# STM32H533 register map
File version: 1.3
CPU: CM33 r0p0, little endian, MPU, FPU, 4 interrupt priority bits
Registers are 32-bit, read-write, reset 0x0 unless marked. A register's access mark holds for its fields unless they carry their own. Offsets are from the block's base; [hi:lo] are bit positions; {n}, {i} and the like mark numbered series.

## CRS — CRS address block description
Base 0x40006000
Same registers: CRS_S 0x50006000
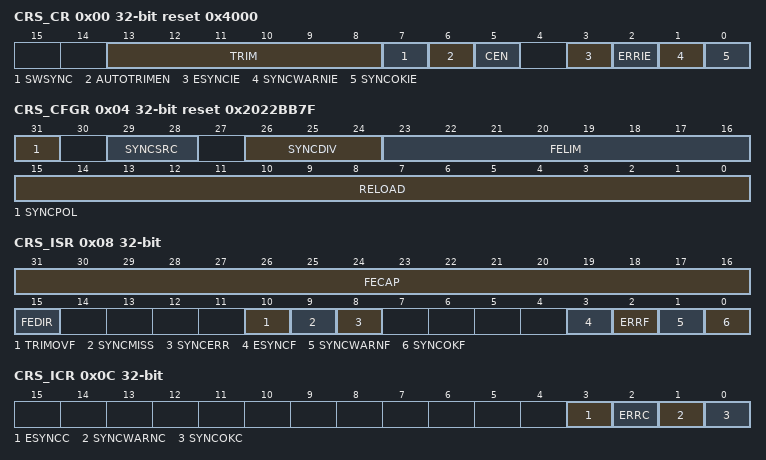
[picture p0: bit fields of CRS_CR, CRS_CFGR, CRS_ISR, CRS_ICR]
0x00 CRS_CR reset 0x4000 — CRS control register
  [13:8] TRIM — HSI48 oscillator smooth trimming
  [7] SWSYNC — Generate software SYNC event
    0=No action; 1=A software SYNC event is generated
  [6] AUTOTRIMEN — Automatic trimming enable
    0=Automatic trimming disabled, TRIM bits can be adjusted by the user; 1=Automatic trimming enabled, TRIM bits are read-only and under hardware control
  [5] CEN — Frequency error counter enable
    0=Frequency error counter disabled; 1=Frequency error counter enabled
  [3] ESYNCIE — Expected SYNC interrupt enable
    0=Expected SYNC (ESYNCF) interrupt disabled; 1=Expected SYNC (ESYNCF) interrupt enabled
  [2] ERRIE — Synchronization or trimming error interrupt enable
    0=Synchronization or trimming error (ERRF) interrupt disabled; 1=Synchronization or trimming error (ERRF) interrupt enabled
  [1] SYNCWARNIE — SYNC warning interrupt enable
    0=SYNC warning (SYNCWARNF) interrupt disabled; 1=SYNC warning (SYNCWARNF) interrupt enabled
  [0] SYNCOKIE — SYNC event OK interrupt enable
    0=SYNC event OK (SYNCOKF) interrupt disabled; 1=SYNC event OK (SYNCOKF) interrupt enabled
0x04 CRS_CFGR reset 0x2022BB7F — CRS configuration register
  [31] SYNCPOL — SYNC polarity selection
    0=SYNC active on rising edge (default); 1=SYNC active on falling edge
  [29:28] SYNCSRC — SYNC signal source selection
    {v}=crs_sync_in_{v+1} selected as SYNC signal source (v=0..3)
  [26:24] SYNCDIV — SYNC divider
    0=SYNC not divided (default); 1=SYNC divided by 2; 2=SYNC divided by 4; 3=SYNC divided by 8; 4=SYNC divided by 16; 5=SYNC divided by 32; 6=SYNC divided by 64; 7=SYNC divided by 128
  [23:16] FELIM — Frequency error limit
  [15:0] RELOAD — Counter reload value
0x08 CRS_ISR ro — CRS interrupt and status register
  [31:16] FECAP — Frequency error capture
  [15] FEDIR — Frequency error direction
    0=Up-counting direction, the actual frequency is above the target; 1=Down-counting direction, the actual frequency is below the target
  [10] TRIMOVF — Trimming overflow or underflow
    0=No trimming error signaled; 1=Trimming error signaled
  [9] SYNCMISS — SYNC missed
    0=No SYNC missed error signaled; 1=SYNC missed error signaled
  [8] SYNCERR — SYNC error
    0=No SYNC error signaled; 1=SYNC error signaled
  [3] ESYNCF — Expected SYNC flag
    0=No expected SYNC signaled; 1=Expected SYNC signaled
  [2] ERRF — Error flag
    0=No synchronization or trimming error signaled; 1=Synchronization or trimming error signaled
  [1] SYNCWARNF — SYNC warning flag
    0=No SYNC warning signaled; 1=SYNC warning signaled
  [0] SYNCOKF — SYNC event OK flag
    0=No SYNC event OK signaled; 1=SYNC event OK signaled
0x0C CRS_ICR — CRS interrupt flag clear register
  [3] ESYNCC — Expected SYNC clear flag
  [2] ERRC — Error clear flag
  [1] SYNCWARNC — SYNC warning clear flag
  [0] SYNCOKC — SYNC event OK clear flag

## DCB — Debug Control Block -- CMSIS's ARMv8-M name for what core_cm0.h/core_cm3.h call CoreDebug (same base address, 0xE000EDF0). Adds DAUTHCTRL (Debug Authentication Control) and DSCSR (Debug Security Control and Status) versus ARMv6-M/ARMv7-M's CoreDebug -- both Security-Extension-related, present regardless of profile. Verified against CMSIS_6 core_cm23.h/core_cm33.h.
Base 0xE000EDF0
0x00 DHCSR — Debug Halting Control and Status Register
  [26] S_RESTART_ST ro — New in ARMv8-M
  [25] S_RESET_ST ro
  [24] S_RETIRE_ST ro
  [20] S_SDE ro — Secure Debug Enabled -- Security Extension only
  [19] S_LOCKUP ro
  [18] S_SLEEP ro
  [17] S_HALT ro
  [16] S_REGRDY ro
  [31:16] DBGKEY wo — Write 0xA05F to enable write access to bits [15:0]; reads as 0
  [5] C_SNAPSTALL
  [3] C_MASKINTS
  [2] C_STEP
  [1] C_HALT
  [0] C_DEBUGEN
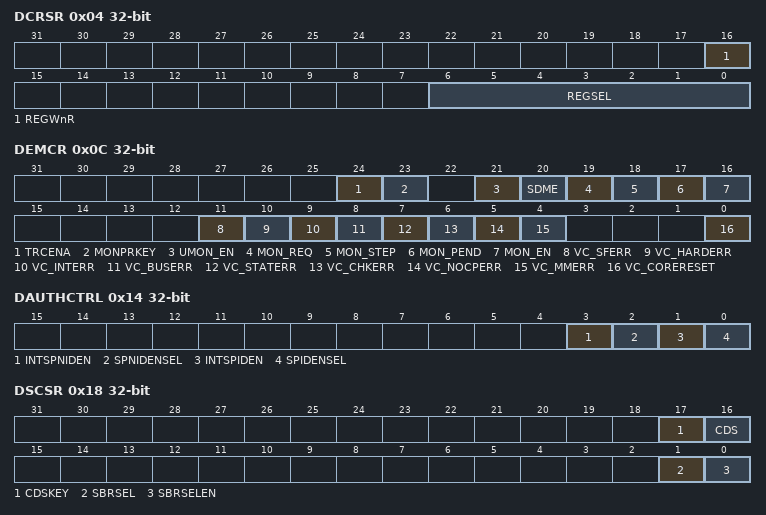
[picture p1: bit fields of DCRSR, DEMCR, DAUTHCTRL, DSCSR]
0x04 DCRSR wo — Debug Core Register Selector Register
  [16] REGWnR, [6:0] REGSEL
0x08 DCRDR — Debug Core Register Data Register
  [31:0] DBGTMP
0x0C DEMCR — Debug Exception and Monitor Control Register
  [24] TRCENA — Trace enable (DWT/ITM/ETM/TPIU) -- only meaningful where those blocks exist
  [23] MONPRKEY — Monitor Pend Request Key
  [21] UMON_EN — Unprivileged Monitor Enable
  [20] SDME — Secure DebugMonitor Enable -- Security Extension only
  [19] MON_REQ — Debug Monitor request
  [18] MON_STEP — Debug Monitor step
  [17] MON_PEND — Debug Monitor pend
  [16] MON_EN — Debug Monitor enable
  [11] VC_SFERR — Debug trap on SecureFault exception -- Security Extension only
  [10] VC_HARDERR — Debug trap on HardFault exception
  [9] VC_INTERR — Debug trap on interrupt/exception service errors
  [8] VC_BUSERR — Debug trap on BusFault exception
  [7] VC_STATERR — Debug trap on UsageFault state error
  [6] VC_CHKERR — Debug trap on UsageFault caused by checking error
  [5] VC_NOCPERR — Debug trap on UsageFault caused by no coprocessor
  [4] VC_MMERR — Debug trap on MemManage exception
  [0] VC_CORERESET — Reset Vector Catch
0x14 DAUTHCTRL — Debug Authentication Control Register -- Security Extension only
  [3] INTSPNIDEN — Internal Secure non-invasive debug enable
  [2] SPNIDENSEL — Secure non-invasive debug enable select
  [1] INTSPIDEN — Internal Secure invasive debug enable
  [0] SPIDENSEL — Secure invasive debug enable select
0x18 DSCSR — Debug Security Control and Status Register -- Security Extension only
  [17] CDSKEY wo — CDS write-enable key
  [16] CDS ro — Current Domain Secure
  [1] SBRSEL — Secure banked register select
  [0] SBRSELEN — Secure banked register select enable
